# PIC18F16Q20 register map
Vendor: Microchip
Registers are 8-bit, read-write, reset 0x0 unless marked. A register's access mark holds for its fields unless they carry their own. Addresses are absolute, and some are shared; only a register's first bit layout is shown; [hi:lo] are bit positions; {n}, {i} and the like mark numbered series; 'fields as' and 'values as' point back to an identical list.

## i3c
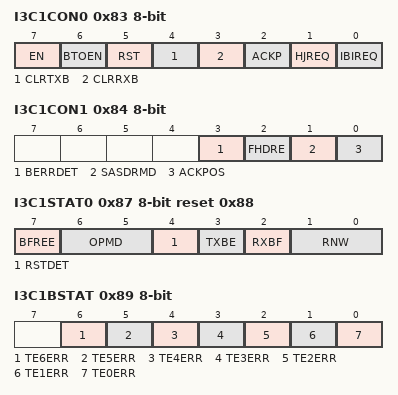
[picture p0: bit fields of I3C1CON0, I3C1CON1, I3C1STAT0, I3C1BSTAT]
0x83 I3C1CON0 — I3C CONTROL REGISTER 0
  [7] EN, [6] BTOEN, [5] RST, [4] CLRTXB, [3] CLRRXB, [2] ACKP, [1] HJREQ, [0] IBIREQ
0x84 I3C1CON1 — I3C CONTROL REGISTER 1
  [3] BERRDET, [2] FHDRE, [1] SASDRMD, [0] ACKPOS
0x85 I3C1RXB ro — I3C RECEIVE BUFFER REGISTER
  [7:0] RXB
0x86 I3C1TXB — I3C TRANSMIT BUFFER REGISTER
  [7:0] TXB
0x87 I3C1STAT0 reset 0x88 — I3C STATUS REGISTER 0
  [7] BFREE ro
  [6:5] OPMD ro
  [4] RSTDET
  [3] TXBE ro
  [2] RXBF ro
  [1:0] RNW — (can only be cleared)
0x88 I3C1STAT1 ro — I3C STATUS REGISTER 1
  [0] TXFNE
0x89 I3C1BSTAT — I3C BUS STATUS REGISTER
  [6] TE6ERR
  [5] TE5ERR
  [4] TE4ERR — Read/Write Information bit
  [3] TE3ERR — Data/Address bit
  [2] TE2ERR
  [1] TE1ERR
  [0] TE0ERR
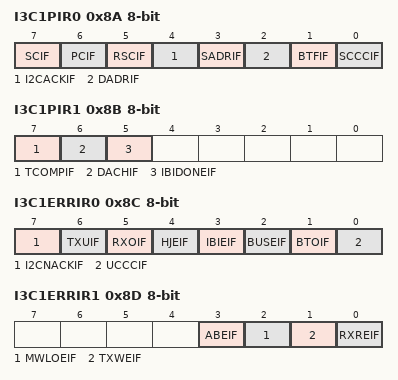
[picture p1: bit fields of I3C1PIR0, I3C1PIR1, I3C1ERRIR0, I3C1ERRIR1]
0x8A I3C1PIR0 — I3C GENERAL INTERRUPT FLAG REGISTER 0
  [7] SCIF, [6] PCIF, [5] RSCIF, [4] I2CACKIF, [3] SADRIF, [2] DADRIF, [1] BTFIF, [0] SCCCIF
0x8B I3C1PIR1 — I3C GENERAL INTERRUPT FLAG REGISTER 1
  [7] TCOMPIF, [6] DACHIF, [5] IBIDONEIF
0x8C I3C1ERRIR0 — I3C ERROR INTERRUPT FLAG REGISTER 0
  [7] I2CNACKIF, [6] TXUIF, [5] RXOIF, [4] HJEIF, [3] IBIEIF, [2] BUSEIF, [1] BTOIF, [0] UCCCIF
0x8D I3C1ERRIR1 — I3C ERROR INTERRUPT FLAG REGISTER 1
  [3] ABEIF, [2] MWLOEIF, [1] TXWEIF, [0] RXREIF
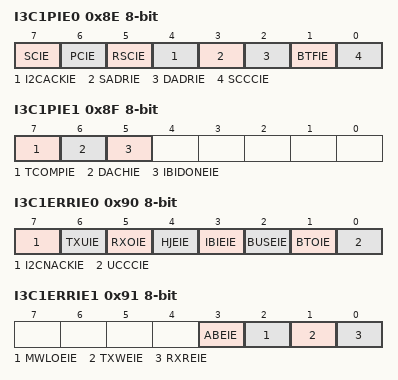
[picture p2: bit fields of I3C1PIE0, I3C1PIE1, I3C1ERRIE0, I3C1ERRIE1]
0x8E I3C1PIE0 — I3C GENERAL INTERRUPT ENABLE REGISTER 0
  [7] SCIE, [6] PCIE, [5] RSCIE, [4] I2CACKIE, [3] SADRIE, [2] DADRIE, [1] BTFIE, [0] SCCCIE
0x8F I3C1PIE1 — I3C GENERAL INTERRUPT ENABLE REGISTER 1
  [7] TCOMPIE, [6] DACHIE, [5] IBIDONEIE
0x90 I3C1ERRIE0 — I3C ERROR INTERRUPT ENABLE REGISTER 0
  [7] I2CNACKIE, [6] TXUIE, [5] RXOIE, [4] HJEIE, [3] IBIEIE, [2] BUSEIE, [1] BTOIE, [0] UCCCIE
0x91 I3C1ERRIE1 — I3C ERROR INTERRUPT ENABLE REGISTER 1
  [3] ABEIE, [2] MWLOEIE, [1] TXWEIE, [0] RXREIE
0x92 I3C1BIDLL — I3C BUS IDLE CONDITION THRESHOLD LOW BYTE REGISTER
  [7:0] BIDLL
0x93 I3C1BIDLH — I3C BUS IDLE CONDITION THRESHOLD HIGH BYTE REGISTER
  [7:0] BIDLH
0x94 I3C1BAVL — I3C BUS AVAILABLE CONDITION THRESHOLD REGISTER
  [7:0] BAVL
0x95 I3C1BTOL — I3C BUS TIMEOUT THRESHOLD LOW BYTE REGISTER
  [7:0] BTOL
0x96 I3C1BTOH — I3C BUS TIMEOUT THRESHOLD HIGH BYTE REGISTER
  [7:0] BTOH
0x97 I3C1IBIMDB — I3C IN-BAND INTERRUPT MANDATORY DATA BYTE REGISTER
  [7:0] IBIMDB
0x98 I3C1RETRY — I3C ARBITRATION REQUEST RETRY LIMIT REGISTER
  [7:0] RETRY
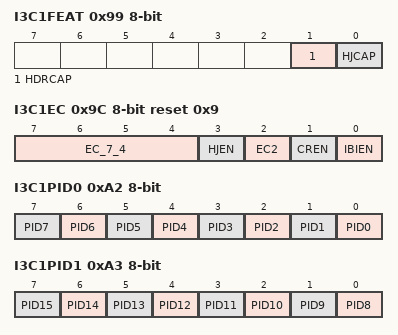
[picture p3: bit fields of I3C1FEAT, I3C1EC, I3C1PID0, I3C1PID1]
0x99 I3C1FEAT — I3C FEATURES REGISTER
  [1] HDRCAP ro, [0] HJCAP
0x9A I3C1SADR — I3C STATIC ADDRESS REGISTER
  [6:0] SADR
0x9B I3C1DADR ro — I3C DYNAMIC ADDRESS REGISTER
  [6:0] DADR
0x9C I3C1EC ro reset 0x9 — I3C EVENT COMMANDS REGISTER
  [7:4] EC_7_4, [3] HJEN, [2] EC2, [1] CREN, [0] IBIEN
0x9D I3C1MWLL — I3C MAXIMUM WRITE LENGTH LOW BYTE REGISTER
  [7:0] MWLL
0x9E I3C1MWLH — I3C MAXIMUM WRITE LENGTH HIGH BYTE REGISTER
  [7:0] MWLH
0x9F I3C1MRLL — I3C MAXIMUM READ LENGTH LOW BYTE REGISTER
  [7:0] MRLL
0xA0 I3C1MRLH — I3C MAXIMUM READ LENGTH HIGH BYTE REGISTER
  [7:0] MRLH
0xA1 I3C1IBIPSZ — I3C IN-BAND INTERRUPT PAYLOAD SIZE REGISTER
  [7:0] IBIPSZ
0xA2 I3C1PID0 — I3C PROVISIONAL ID REGISTER 0
  [n] PID{n} (n=0..7)
0xA3 I3C1PID1 — I3C PROVISIONAL ID REGISTER 1
  [n-8] PID{n} (n=8..15)
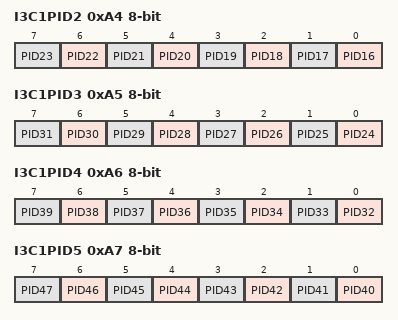
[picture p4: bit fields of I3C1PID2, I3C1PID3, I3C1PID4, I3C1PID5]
0xA4 I3C1PID2 — I3C PROVISIONAL ID REGISTER 2
  [n-16] PID{n} (n=16..23)
0xA5 I3C1PID3 — I3C PROVISIONAL ID REGISTER 3
  [n-24] PID{n} (n=24..31)
0xA6 I3C1PID4 — I3C PROVISIONAL ID REGISTER 4
  [n-32] PID{n} (n=32..39)
0xA7 I3C1PID5 — I3C PROVISIONAL ID REGISTER 5
  [n-40] PID{n} (n=40..47)
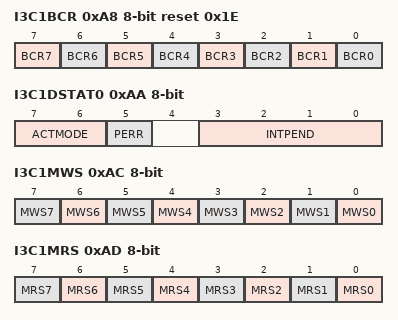
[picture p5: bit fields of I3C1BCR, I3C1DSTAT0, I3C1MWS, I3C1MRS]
0xA8 I3C1BCR reset 0x1E — I3C BUS CHARACTERISTICS REGISTER
  [n] BCR{n} ro (n=1..7), [0] BCR0
0xA9 I3C1DCR reset 0xC6 — I3C DEVICE CHARACTERISTICS REGISTER
  [7:0] DCR
0xAA I3C1DSTAT0 — I3C DEVICE STATUS REGISTER 0
  [7:6] ACTMODE
  [5] PERR ro
  [3:0] INTPEND — Data/Address bit
0xAB I3C1DSTAT1 — I3C DEVICE STATUS REGISTER 1
  [7:0] VRSV
0xAC I3C1MWS — I3C MAXIMUM WRITE SPEED REGISTER
  [n] MWS{n} (n=0..7)
0xAD I3C1MRS — I3C MAXIMUM READ SPEED REGISTER
  [n] MRS{n} (n=0..7)
0xAE I3C1MRTL — I3C MAXIMUM READ TURNAROUND LOW BYTE REGISTER
  [7:0] MRTL
0xAF I3C1MRTH — I3C MAXIMUM READ TURNAROUND HIGH BYTE REGISTER
  [7:0] MRTH
0xB0 I3C1MRTU — I3C MAXIMUM READ TURNAROUND UPPER BYTE REGISTER
  [7:0] MRTU
0xB1 I3C1RSTACT reset 0xFF — I3C RSTACT CCC DEFINING BYTE REGISTER
  [7:0] RSTACT
0xB2 I3C1BUSCXT ro — I3C BUS CONTEXT REGISTER
  [7:0] BUSCXT
0xB3 I3C1CCC ro — I3C CCC RECEIVED REGISTER
  [7:0] CCC
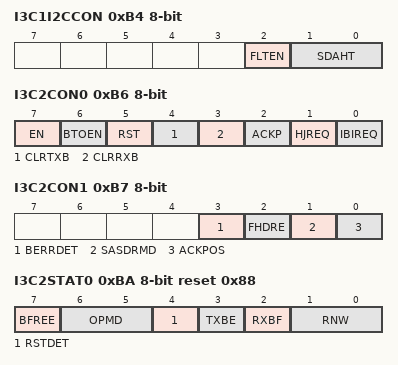
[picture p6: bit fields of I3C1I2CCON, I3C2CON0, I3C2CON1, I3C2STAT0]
0xB4 I3C1I2CCON — I3C LEGACY I2C CONTROL REGISTER
  [2] FLTEN, [1:0] SDAHT
0xB5 I3C1CLK — I3C CLOCK SELECTION REGISTER
  [3:0] CLK
0xB6 I3C2CON0 — I3C CONTROL REGISTER 0
  fields as I3C1CON0
0xB7 I3C2CON1 — I3C CONTROL REGISTER 1
  [3] BERRDET, [2] FHDRE, [1] SASDRMD, [0] ACKPOS
0xB8 I3C2RXB ro — I3C RECEIVE BUFFER REGISTER
  [7:0] RXB
0xB9 I3C2TXB — I3C TRANSMIT BUFFER REGISTER
  [7:0] TXB
0xBA I3C2STAT0 reset 0x88 — I3C STATUS REGISTER 0
  fields as I3C1STAT0
0xBB I3C2STAT1 ro — I3C STATUS REGISTER 1
  [0] TXFNE
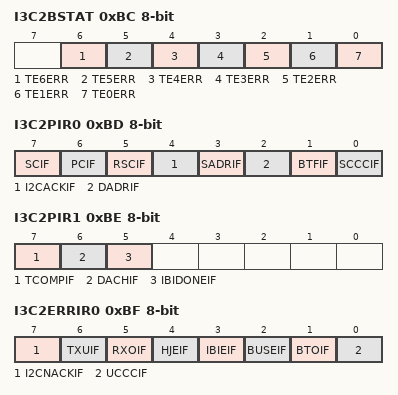
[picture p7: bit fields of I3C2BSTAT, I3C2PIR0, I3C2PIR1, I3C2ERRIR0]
0xBC I3C2BSTAT — I3C BUS STATUS REGISTER
  fields as I3C1BSTAT
0xBD I3C2PIR0 — I3C GENERAL INTERRUPT FLAG REGISTER 0
  fields as I3C1PIR0
0xBE I3C2PIR1 — I3C GENERAL INTERRUPT FLAG REGISTER 1
  [7] TCOMPIF, [6] DACHIF, [5] IBIDONEIF
0xBF I3C2ERRIR0 — I3C ERROR INTERRUPT FLAG REGISTER 0
  fields as I3C1ERRIR0
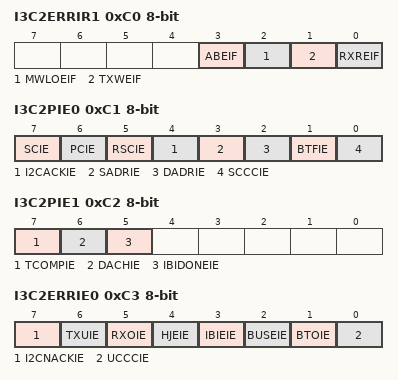
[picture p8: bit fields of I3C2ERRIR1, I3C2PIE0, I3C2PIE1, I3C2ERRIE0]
0xC0 I3C2ERRIR1 — I3C ERROR INTERRUPT FLAG REGISTER 1
  [3] ABEIF, [2] MWLOEIF, [1] TXWEIF, [0] RXREIF
0xC1 I3C2PIE0 — I3C GENERAL INTERRUPT ENABLE REGISTER 0
  fields as I3C1PIE0
0xC2 I3C2PIE1 — I3C GENERAL INTERRUPT ENABLE REGISTER 1
  [7] TCOMPIE, [6] DACHIE, [5] IBIDONEIE
0xC3 I3C2ERRIE0 — I3C ERROR INTERRUPT ENABLE REGISTER 0
  fields as I3C1ERRIE0
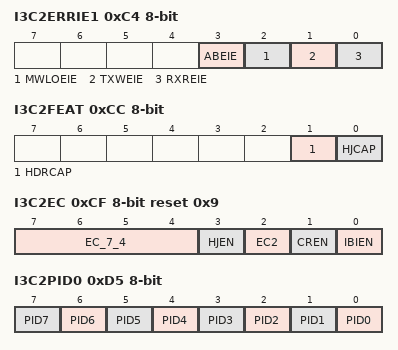
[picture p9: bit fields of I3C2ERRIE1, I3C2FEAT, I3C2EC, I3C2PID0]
0xC4 I3C2ERRIE1 — I3C ERROR INTERRUPT ENABLE REGISTER 1
  [3] ABEIE, [2] MWLOEIE, [1] TXWEIE, [0] RXREIE
0xC5 I3C2BIDLL — I3C BUS IDLE CONDITION THRESHOLD LOW BYTE REGISTER
  [7:0] BIDLL
0xC6 I3C2BIDLH — I3C BUS IDLE CONDITION THRESHOLD HIGH BYTE REGISTER
  [7:0] BIDLH
0xC7 I3C2BAVL — I3C BUS AVAILABLE CONDITION THRESHOLD REGISTER
  [7:0] BAVL
0xC8 I3C2BTOL — I3C BUS TIMEOUT THRESHOLD LOW BYTE REGISTER
  [7:0] BTOL
0xC9 I3C2BTOH — I3C BUS TIMEOUT THRESHOLD HIGH BYTE REGISTER
  [7:0] BTOH
0xCA I3C2IBIMDB — I3C IN-BAND INTERRUPT MANDATORY DATA BYTE REGISTER
  [7:0] IBIMDB
0xCB I3C2RETRY — I3C ARBITRATION REQUEST RETRY LIMIT REGISTER
  [7:0] RETRY
0xCC I3C2FEAT — I3C FEATURES REGISTER
  [1] HDRCAP ro, [0] HJCAP
0xCD I3C2SADR — I3C STATIC ADDRESS REGISTER
  [6:0] SADR
0xCE I3C2DADR ro — I3C DYNAMIC ADDRESS REGISTER
  [6:0] DADR
0xCF I3C2EC ro reset 0x9 — I3C EVENT COMMANDS REGISTER
  [7:4] EC_7_4, [3] HJEN, [2] EC2, [1] CREN, [0] IBIEN
0xD0 I3C2MWLL — I3C MAXIMUM WRITE LENGTH LOW BYTE REGISTER
  [7:0] MWLL
0xD1 I3C2MWLH — I3C MAXIMUM WRITE LENGTH HIGH BYTE REGISTER
  [7:0] MWLH
0xD2 I3C2MRLL — I3C MAXIMUM READ LENGTH LOW BYTE REGISTER
  [7:0] MRLL
0xD3 I3C2MRLH — I3C MAXIMUM READ LENGTH HIGH BYTE REGISTER
  [7:0] MRLH
0xD4 I3C2IBIPSZ — I3C IN-BAND INTERRUPT PAYLOAD SIZE REGISTER
  [7:0] IBIPSZ
0xD5 I3C2PID0 — I3C PROVISIONAL ID REGISTER 0
  [n] PID{n} (n=0..7)
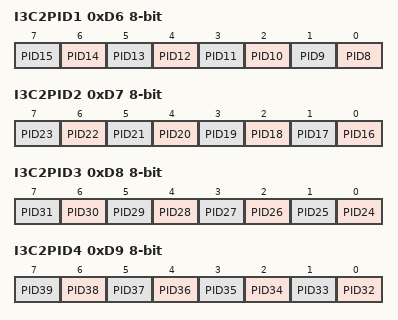
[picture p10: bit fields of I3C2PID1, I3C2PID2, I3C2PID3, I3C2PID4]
0xD6 I3C2PID1 — I3C PROVISIONAL ID REGISTER 1
  [n-8] PID{n} (n=8..15)
0xD7 I3C2PID2 — I3C PROVISIONAL ID REGISTER 2
  [n-16] PID{n} (n=16..23)
0xD8 I3C2PID3 — I3C PROVISIONAL ID REGISTER 3
  [n-24] PID{n} (n=24..31)
0xD9 I3C2PID4 — I3C PROVISIONAL ID REGISTER 4
  [n-32] PID{n} (n=32..39)
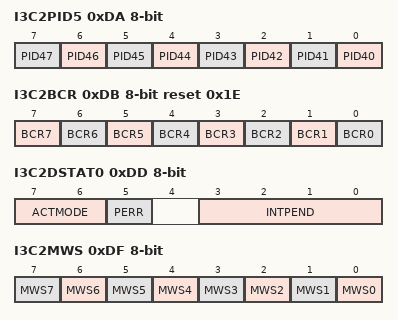
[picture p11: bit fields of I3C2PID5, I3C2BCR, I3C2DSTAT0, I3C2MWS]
0xDA I3C2PID5 — I3C PROVISIONAL ID REGISTER 5
  [n-40] PID{n} (n=40..47)
0xDB I3C2BCR reset 0x1E — I3C BUS CHARACTERISTICS REGISTER
  [n] BCR{n} ro (n=1..7), [0] BCR0
0xDC I3C2DCR reset 0xC6 — I3C DEVICE CHARACTERISTICS REGISTER
  [7:0] DCR
0xDD I3C2DSTAT0 — I3C DEVICE STATUS REGISTER 0
  [7:6] ACTMODE
  [5] PERR ro
  [3:0] INTPEND — Data/Address bit
0xDE I3C2DSTAT1 — I3C DEVICE STATUS REGISTER 1
  [7:0] VRSV
0xDF I3C2MWS — I3C MAXIMUM WRITE SPEED REGISTER
  [n] MWS{n} (n=0..7)
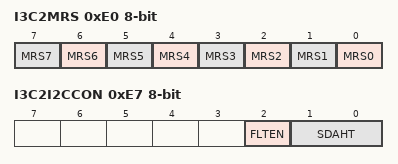
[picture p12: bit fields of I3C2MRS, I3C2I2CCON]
0xE0 I3C2MRS — I3C MAXIMUM READ SPEED REGISTER
  [n] MRS{n} (n=0..7)
0xE1 I3C2MRTL — I3C MAXIMUM READ TURNAROUND LOW BYTE REGISTER
  [7:0] MRTL
0xE2 I3C2MRTH — I3C MAXIMUM READ TURNAROUND HIGH BYTE REGISTER
  [7:0] MRTH
0xE3 I3C2MRTU — I3C MAXIMUM READ TURNAROUND UPPER BYTE REGISTER
  [7:0] MRTU
0xE4 I3C2RSTACT reset 0xFF — I3C RSTACT CCC DEFINING BYTE REGISTER
  [7:0] RSTACT
0xE5 I3C2BUSCXT ro — I3C BUS CONTEXT REGISTER
  [7:0] BUSCXT
0xE6 I3C2CCC ro — I3C CCC RECEIVED REGISTER
  [7:0] CCC
0xE7 I3C2I2CCON — I3C LEGACY I2C CONTROL REGISTER
  [2] FLTEN, [1:0] SDAHT
0xE8 I3C2CLK — I3C CLOCK SELECTION REGISTER
  [3:0] CLK
